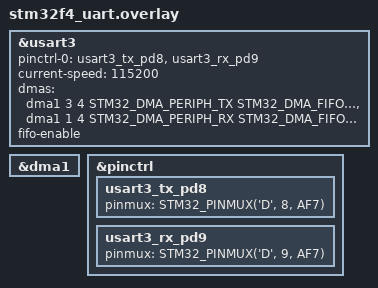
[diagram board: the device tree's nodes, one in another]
&usart3 {
    status = "okay";
	pinctrl-0 = <&usart3_tx_pd8 &usart3_rx_pd9>;
	pinctrl-names = "default";
	current-speed = <115200>;

     dmas = <&dma1 3 4 STM32_DMA_PERIPH_TX STM32_DMA_FIFO_FULL>,
           <&dma1 1 4 STM32_DMA_PERIPH_RX STM32_DMA_FIFO_FULL>;
    dma-names = "tx", "rx";
    fifo-enable;
	
};

&dma1 {
    status = "okay";
};



&pinctrl {
    usart3_tx_pd8: usart3_tx_pd8 {
        pinmux = <STM32_PINMUX('D', 8, AF7)>;

    };


    usart3_rx_pd9: usart3_rx_pd9 {
        pinmux = <STM32_PINMUX('D', 9, AF7)>;
    };


};



